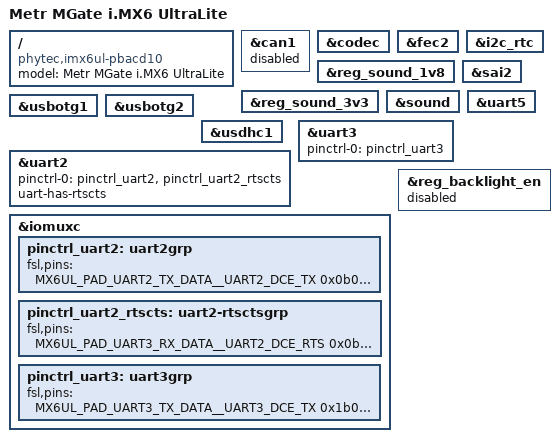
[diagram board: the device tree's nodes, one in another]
/*
 * Copyright (C) 2017 Aravinth Panch <aravinth.panchadcharam@nbt.ag>
 *
 * This file is dual-licensed: you can use it either under the terms
 * of the GPL or the X11 license, at your option. Note that this dual
 * licensing only applies to this file, and not this project as a
 * whole.
 *
 *  a) This file is free software; you can redistribute it and/or
 *     modify it under the terms of the GNU General Public License as
 *     published by the Free Software Foundation; either version 2 of the
 *     License, or (at your option) any later version.
 *
 *     This file is distributed in the hope that it will be useful,
 *     but WITHOUT ANY WARRANTY; without even the implied warranty of
 *     MERCHANTABILITY or FITNESS FOR A PARTICULAR PURPOSE.  See the
 *     GNU General Public License for more details.
 *
 * Or, alternatively,
 *
 *  b) Permission is hereby granted, free of charge, to any person
 *     obtaining a copy of this software and associated documentation
 *     files (the "Software"), to deal in the Software without
 *     restriction, including without limitation the rights to use,
 *     copy, modify, merge, publish, distribute, sublicense, and/or
 *     sell copies of the Software, and to permit persons to whom the
 *     Software is furnished to do so, subject to the following
 *     conditions:
 *
 *     The above copyright notice and this permission notice shall be
 *     included in all copies or substantial portions of the Software.
 *
 *     THE SOFTWARE IS PROVIDED "AS IS", WITHOUT WARRANTY OF ANY KIND,
 *     EXPRESS OR IMPLIED, INCLUDING BUT NOT LIMITED TO THE WARRANTIES
 *     OF MERCHANTABILITY, FITNESS FOR A PARTICULAR PURPOSE AND
 *     NONINFRINGEMENT. IN NO EVENT SHALL THE AUTHORS OR COPYRIGHT
 *     HOLDERS BE LIABLE FOR ANY CLAIM, DAMAGES OR OTHER LIABILITY,
 *     WHETHER IN AN ACTION OF CONTRACT, TORT OR OTHERWISE, ARISING
 *     FROM, OUT OF OR IN CONNECTION WITH THE SOFTWARE OR THE USE OR
 *     OTHER DEALINGS IN THE SOFTWARE.
 */


/dts-v1/;
#include "imx6ul.dtsi"
#include "imx6ul-phytec-phycore-som.dtsi"
#include "imx6ul-phytec-phyboard-segin.dtsi"
#include "imx6ul-phytec-segin-peb-av-02.dtsi"
#include "imx6ul-phytec-segin-peb-eval-01.dtsi"


/ {
	model = "Metr MGate i.MX6 UltraLite";
	compatible = "phytec,imx6ul-pbacd10", "phytec,imx6ul-pcl063","fsl,imx6ul";
};

&can1 {
	status = "disabled";
};

&codec {
	status = "okay";
};

&fec2 {
	status = "okay";
};

&i2c_rtc {
	status = "okay";
};


&reg_sound_1v8 {
	status = "okay";
};

&reg_sound_3v3 {
	status = "okay";
};

&sai2 {
	status = "okay";
};

&sound {
	status = "okay";
};

&uart5 {
	status = "okay";
};

&usbotg1 {
	status = "okay";
};

&usbotg2 {
	status = "okay";
};

&usdhc1 {
	status = "okay";
};

&uart2 {
        pinctrl-names = "default";
        pinctrl-0 = <&pinctrl_uart2 &pinctrl_uart2_rtscts>;
        uart-has-rtscts;
        status = "okay";
};

&uart3 {
        pinctrl-names = "default";
        pinctrl-0 = <&pinctrl_uart3>;
        status = "okay";
};

&iomuxc {
    pinctrl_uart2: uart2grp {
            fsl,pins = <
                    MX6UL_PAD_UART2_TX_DATA__UART2_DCE_TX   0x0b0b0
                    MX6UL_PAD_UART2_RX_DATA__UART2_DCE_RX   0x0b0b0
            >;
    };

    pinctrl_uart2_rtscts: uart2-rtsctsgrp {
            fsl,pins = <
                    MX6UL_PAD_UART3_RX_DATA__UART2_DCE_RTS  0x0b0b0
                    MX6UL_PAD_UART3_TX_DATA__UART2_DCE_CTS  0x0b0b0
            >;
    };

    pinctrl_uart3: uart3grp {
            fsl,pins = <
                    MX6UL_PAD_UART3_TX_DATA__UART3_DCE_TX   0x1b0b1
                    MX6UL_PAD_UART3_RX_DATA__UART3_DCE_RX   0x1b0b1
            >;
    };
};

&reg_backlight_en {
	status = "disabled";
};
